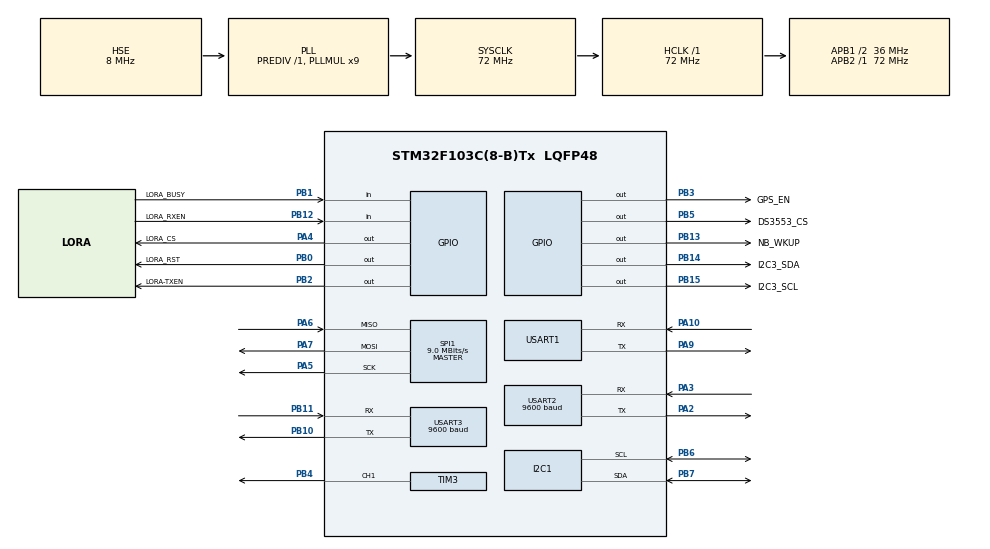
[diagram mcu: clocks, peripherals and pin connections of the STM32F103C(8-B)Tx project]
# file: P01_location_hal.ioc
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Mcu.Family=STM32F1
Mcu.Name=STM32F103C(8-B)Tx
Mcu.Package=LQFP48
NVIC.PriorityGroup=NVIC_PRIORITYGROUP_4
PA10.Mode=Asynchronous
PA10.Signal=USART1_RX
PA13.Mode=Serial_Wire
PA13.Signal=SYS_JTMS-SWDIO
PA14.Mode=Serial_Wire
PA14.Signal=SYS_JTCK-SWCLK
PA2.Mode=Asynchronous
PA2.Signal=USART2_TX
PA3.Mode=Asynchronous
PA3.Signal=USART2_RX
PA4.GPIO_Label=LORA_CS
PA4.GPIO_Speed=GPIO_SPEED_FREQ_HIGH
PA4.PinState=GPIO_PIN_SET
PA4.Signal=GPIO_Output
PA5.Mode=Full_Duplex_Master
PA5.Signal=SPI1_SCK
PA6.Mode=Full_Duplex_Master
PA6.Signal=SPI1_MISO
PA7.Mode=Full_Duplex_Master
PA7.Signal=SPI1_MOSI
PA9.Mode=Asynchronous
PA9.Signal=USART1_TX
PB0.GPIO_Label=LORA_RST
PB0.GPIO_Speed=GPIO_SPEED_FREQ_HIGH
PB0.Signal=GPIO_Output
PB1.GPIO_Label=LORA_BUSY 
PB1.Signal=GPIO_Input
PB10.Mode=Asynchronous
PB10.Signal=USART3_TX
PB11.Mode=Asynchronous
PB11.Signal=USART3_RX
PB12.GPIO_Label=LORA_RXEN 
PB12.Signal=GPIO_Input
PB13.GPIO_Label=NB_WKUP
PB13.GPIO_PuPd=GPIO_NOPULL
PB13.GPIO_Speed=GPIO_SPEED_FREQ_HIGH
PB13.Signal=GPIO_Output
PB14.GPIO_Label=I2C3_SDA
PB14.GPIO_ModeDefaultOutputPP=GPIO_MODE_OUTPUT_OD
PB14.GPIO_PuPd=GPIO_PULLUP
PB14.GPIO_Speed=GPIO_SPEED_FREQ_HIGH
PB14.PinState=GPIO_PIN_SET
PB14.Signal=GPIO_Output
PB15.GPIO_Label=I2C3_SCL
PB15.GPIO_ModeDefaultOutputPP=GPIO_MODE_OUTPUT_OD
PB15.GPIO_PuPd=GPIO_PULLUP
PB15.GPIO_Speed=GPIO_SPEED_FREQ_HIGH
PB15.PinState=GPIO_PIN_SET
PB15.Signal=GPIO_Output
PB2.GPIO_Label=LORA-TXEN 
PB2.GPIO_Speed=GPIO_SPEED_FREQ_HIGH
PB2.Signal=GPIO_Output
PB3.GPIO_Label=GPS_EN
PB3.GPIO_Speed=GPIO_SPEED_FREQ_HIGH
PB3.PinState=GPIO_PIN_SET
PB3.Signal=GPIO_Output
PB4.Signal=S_TIM3_CH1
PB5.GPIO_Label=DS3553_CS 
PB5.GPIO_Speed=GPIO_SPEED_FREQ_HIGH
PB5.PinState=GPIO_PIN_SET
PB5.Signal=GPIO_Output
PB6.Mode=I2C
PB6.Signal=I2C1_SCL
PB7.Mode=I2C
PB7.Signal=I2C1_SDA
PC14-OSC32_IN.Mode=LSE-External-Oscillator
PC14-OSC32_IN.Signal=RCC_OSC32_IN
PC15-OSC32_OUT.Mode=LSE-External-Oscillator
PC15-OSC32_OUT.Signal=RCC_OSC32_OUT
PD0-OSC_IN.Mode=HSE-External-Oscillator
PD0-OSC_IN.Signal=RCC_OSC_IN
PD1-OSC_OUT.Mode=HSE-External-Oscillator
PD1-OSC_OUT.Signal=RCC_OSC_OUT
ProjectManager.HeapSize=0x400
ProjectManager.StackSize=0x800
ProjectManager.TargetToolchain=MDK-ARM V5.32
RCC.AHBFreq_Value=72000000
RCC.APB1CLKDivider=RCC_HCLK_DIV2
RCC.APB1Freq_Value=36000000
RCC.APB1TimFreq_Value=72000000
RCC.APB2Freq_Value=72000000
RCC.APB2TimFreq_Value=72000000
RCC.HCLKFreq_Value=72000000
RCC.PLLMUL=RCC_PLL_MUL9
RCC.PLLSourceVirtual=RCC_PLLSOURCE_HSE
RCC.SYSCLKFreq_VALUE=72000000
RCC.SYSCLKSource=RCC_SYSCLKSOURCE_PLLCLK
RCC.USBFreq_Value=72000000
SH.S_TIM3_CH1.0=TIM3_CH1,PWM Generation1 CH1
SPI1.BaudRatePrescaler=SPI_BAUDRATEPRESCALER_8
SPI1.CalculateBaudRate=9.0 MBits/s
SPI1.Direction=SPI_DIRECTION_2LINES
SPI1.Mode=SPI_MODE_MASTER
SPI1.VirtualType=VM_MASTER
TIM3.Channel-PWM\ Generation1\ CH1=TIM_CHANNEL_1
TIM3.Prescaler=72-1
USART1.VirtualMode=VM_ASYNC
USART2.BaudRate=9600
USART2.VirtualMode=VM_ASYNC
USART3.BaudRate=9600
USART3.VirtualMode=VM_ASYNC
VP_RTC_VS_RTC_Activate.Mode=RTC_Enabled
VP_TIM3_VS_ClockSourceINT.Mode=Internal
board=custom

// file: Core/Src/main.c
/* USER CODE BEGIN Header */
/**
  ******************************************************************************
  * @file           : main.c
  * @brief          : Main program body
  ******************************************************************************
  * @attention
  *
  * Copyright (c) 2025 STMicroelectronics.
  * All rights reserved.
  *
  * This software is licensed under terms that can be found in the LICENSE file
  * in the root directory of this software component.
  * If no LICENSE file comes with this software, it is provided AS-IS.
  *
  ******************************************************************************
  */
/* USER CODE END Header */
#include "main.h"
#include "i2c.h"
#include "rtc.h"
#include "spi.h"
#include "tim.h"
#include "usart.h"
#include "gpio.h"

/* USER CODE BEGIN Includes */
// #include "Int_AT6558R.h"
// #include "Int_QS100.h"
// #include "Int_Lora.h"
#include "App_Location.h"
#include "App_Detect_Fall.h"
#include "Inf_Buzzer.h"
#include "app_rtos.h"
/* USER CODE END Includes */

void SystemClock_Config(void);

int main(void)
{

  /* MCU Configuration--------------------------------------------------------*/

  /* Reset of all peripherals, Initializes the Flash interface and the Systick. */
  HAL_Init();

  /* Configure the system clock */
  SystemClock_Config();

  /* Initialize all configured peripherals */
  MX_GPIO_Init();
  MX_USART1_UART_Init();
  MX_I2C1_Init();
  MX_USART2_UART_Init();
  MX_USART3_UART_Init();
  MX_SPI1_Init();
  MX_RTC_Init();
  MX_TIM3_Init();
  /* USER CODE BEGIN 2 */
  // Int_AT6558R_Init();
  // Int_QS100_Init();
  // uint8_t data[10]="HELLO";
  // Int_QS100_Send_Data(data,5);
  // uint8_t status = Int_Lora_Init();

  App_FreeRTOS_Start();
  // uint8_t buzzer_flag = 0;

  // Driver_I2C2_Init();
  // Int_MPU6050_Init();

  // App_Exit_Low_Power();
  // App_Location_Get_Step_Count();
  // App_Location_Get_GPS_Data();
  // App_Location_Data_to_JSON();
  // App_Location_Send_Data();
  // APP_Enter_Low_Power();
  // Inf_Buzzer_Alarm(1);

  /* USER CODE END 2 */

  /* Infinite loop */
  /* USER CODE BEGIN WHILE */
  while (1)
  {
    // if(app_fall_detect()==true)
    // {
    //     // 检测到跌倒，触发报警
    //     // 例如：蜂鸣器报警、发送警报信息等
    //     buzzer_flag = 1;

    //   // 发送警报信息
    //   App_Exit_Low_Power();
    //   App_Location_Get_Step_Count();
    //   App_Location_Get_GPS_Data();
    //   App_Location_Data_to_JSON();
    //   App_Location_Send_Data();
    //   APP_Enter_Low_Power();
    // }
    // if (buzzer_flag == 1)
    // {
    //   Inf_Buzzer_Alarm(0);
    // }
    /* USER CODE END WHILE */

  }
}

void SystemClock_Config(void)
{
  RCC_OscInitTypeDef RCC_OscInitStruct = {0};
  RCC_ClkInitTypeDef RCC_ClkInitStruct = {0};
  RCC_PeriphCLKInitTypeDef PeriphClkInit = {0};

  /** Initializes the RCC Oscillators according to the specified parameters
  * in the RCC_OscInitTypeDef structure.
  */
  RCC_OscInitStruct.OscillatorType = RCC_OSCILLATORTYPE_LSI|RCC_OSCILLATORTYPE_HSE;
  RCC_OscInitStruct.HSEState = RCC_HSE_ON;
  RCC_OscInitStruct.HSEPredivValue = RCC_HSE_PREDIV_DIV1;
  RCC_OscInitStruct.HSIState = RCC_HSI_ON;
  RCC_OscInitStruct.LSIState = RCC_LSI_ON;
  RCC_OscInitStruct.PLL.PLLState = RCC_PLL_ON;
  RCC_OscInitStruct.PLL.PLLSource = RCC_PLLSOURCE_HSE;
  RCC_OscInitStruct.PLL.PLLMUL = RCC_PLL_MUL9;
  if (HAL_RCC_OscConfig(&RCC_OscInitStruct) != HAL_OK)
  {
    Error_Handler();
  }

  /** Initializes the CPU, AHB and APB buses clocks
  */
  RCC_ClkInitStruct.ClockType = RCC_CLOCKTYPE_HCLK|RCC_CLOCKTYPE_SYSCLK
                              |RCC_CLOCKTYPE_PCLK1|RCC_CLOCKTYPE_PCLK2;
  RCC_ClkInitStruct.SYSCLKSource = RCC_SYSCLKSOURCE_PLLCLK;
  RCC_ClkInitStruct.AHBCLKDivider = RCC_SYSCLK_DIV1;
  RCC_ClkInitStruct.APB1CLKDivider = RCC_HCLK_DIV2;
  RCC_ClkInitStruct.APB2CLKDivider = RCC_HCLK_DIV1;

  if (HAL_RCC_ClockConfig(&RCC_ClkInitStruct, FLASH_LATENCY_2) != HAL_OK)
  {
    Error_Handler();
  }
  PeriphClkInit.PeriphClockSelection = RCC_PERIPHCLK_RTC;
  PeriphClkInit.RTCClockSelection = RCC_RTCCLKSOURCE_LSI;
  if (HAL_RCCEx_PeriphCLKConfig(&PeriphClkInit) != HAL_OK)
  {
    Error_Handler();
  }
}

void Error_Handler(void)
{
  __disable_irq();
  while (1)
  {
  }
}
